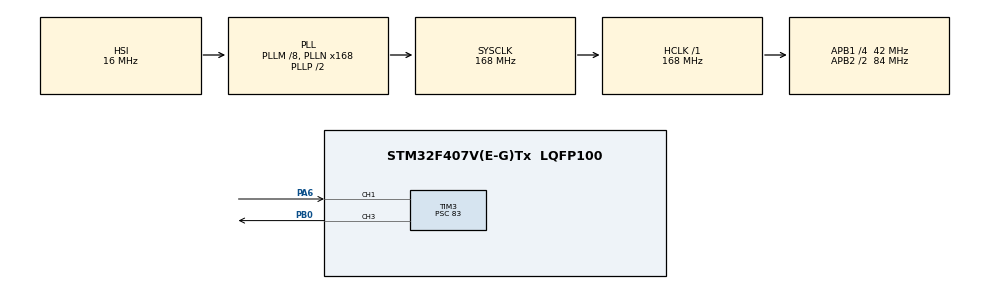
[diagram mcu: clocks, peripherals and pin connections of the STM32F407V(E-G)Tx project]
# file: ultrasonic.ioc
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Mcu.Family=STM32F4
Mcu.Name=STM32F407V(E-G)Tx
Mcu.Package=LQFP100
NVIC.PriorityGroup=NVIC_PRIORITYGROUP_4
NVIC.TIM3_IRQn=true\:1\:0\:true\:false\:true\:true\:true
PA6.Signal=S_TIM3_CH1
PB0.Signal=S_TIM3_CH3
PH0-OSC_IN.Mode=HSE-External-Oscillator
PH0-OSC_IN.Signal=RCC_OSC_IN
PH1-OSC_OUT.Mode=HSE-External-Oscillator
PH1-OSC_OUT.Signal=RCC_OSC_OUT
ProjectManager.HeapSize=0x200
ProjectManager.StackSize=0x400
ProjectManager.TargetToolchain=MDK-ARM V5
RCC.48MHZClocksFreq_Value=84000000
RCC.AHBFreq_Value=168000000
RCC.APB1CLKDivider=RCC_HCLK_DIV4
RCC.APB1Freq_Value=42000000
RCC.APB1TimFreq_Value=84000000
RCC.APB2CLKDivider=RCC_HCLK_DIV2
RCC.APB2Freq_Value=84000000
RCC.APB2TimFreq_Value=168000000
RCC.CortexFreq_Value=168000000
RCC.HCLKFreq_Value=168000000
RCC.HSE_VALUE=25000000
RCC.HSI_VALUE=16000000
RCC.LSE_VALUE=32768
RCC.PLLM=8
RCC.PLLN=168
RCC.SYSCLKFreq_VALUE=168000000
RCC.SYSCLKSource=RCC_SYSCLKSOURCE_PLLCLK
RCC.VCOOutputFreq_Value=336000000
SH.S_TIM3_CH1.0=TIM3_CH1,Input_Capture1_from_TI1
SH.S_TIM3_CH1.1=TIM3_CH1,Input_Capture2_from_TI1
SH.S_TIM3_CH3.0=TIM3_CH3,PWM Generation3 CH3
TIM3.Channel-Input_Capture1_from_TI1=TIM_CHANNEL_1
TIM3.Channel-Input_Capture2_from_TI1=TIM_CHANNEL_2
TIM3.Channel-PWM\ Generation3\ CH3=TIM_CHANNEL_3
TIM3.Period=33332
TIM3.Prescaler=83
TIM3.Pulse-PWM\ Generation3\ CH3=19
VP_TIM3_VS_ClockSourceINT.Mode=Internal
board=custom

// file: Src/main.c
/* USER CODE BEGIN Header */
/**
  ******************************************************************************
  * @file           : main.c
  * @brief          : Main program body
  ******************************************************************************
  * @attention
  *
  * <h2><center>&copy; Copyright (c) 2020 STMicroelectronics.
  * All rights reserved.</center></h2>
  *
  * This software component is licensed by ST under BSD 3-Clause license,
  * the "License"; You may not use this file except in compliance with the
  * License. You may obtain a copy of the License at:
  *                        opensource.org/licenses/BSD-3-Clause
  *
  ******************************************************************************
  */
/* USER CODE END Header */

#include "main.h"
#include "tim.h"
#include "gpio.h"

/* USER CODE BEGIN Includes */
#include "LiquidCrystal.h"

/* USER CODE END Includes */

/* USER CODE BEGIN PV */
uint16_t echo_start = 0;
uint16_t RTT = 0;
char LCDstring[16] = "";
float distance = 0;
/* USER CODE END PV */

void SystemClock_Config(void);

int main(void)
{

  /* MCU Configuration--------------------------------------------------------*/

  /* Reset of all peripherals, Initializes the Flash interface and the Systick. */
  HAL_Init();

  /* Configure the system clock */
  SystemClock_Config();

  /* Initialize all configured peripherals */
  MX_GPIO_Init();
  MX_TIM3_Init();
  /* USER CODE BEGIN 2 */
	HAL_TIM_PWM_Start(&htim3, TIM_CHANNEL_3);
	HAL_TIM_IC_Start_IT(&htim3, TIM_CHANNEL_1);
	HAL_TIM_IC_Start_IT(&htim3, TIM_CHANNEL_2);
	LiquidCrystal(GPIOD, GPIO_PIN_9, GPIO_PIN_10, GPIO_PIN_11,
			     GPIO_PIN_0, GPIO_PIN_1, GPIO_PIN_2, GPIO_PIN_3);
  /* USER CODE END 2 */

  /* Infinite loop */
  while (1)
  {

    /* USER CODE BEGIN 3 */
		clear();

		setCursor(0,0);
		sprintf(LCDstring, "RTT = %d", 342*RTT); // micro-meter
		print(LCDstring);

		setCursor(0,1);
		distance = 0.0348*RTT/2.0 - 0.4472;
		sprintf(LCDstring, "dis: %f", distance);
		print(LCDstring);
		HAL_Delay(200);
  }
  /* USER CODE END 3 */
}

void SystemClock_Config(void)
{
  RCC_OscInitTypeDef RCC_OscInitStruct = {0};
  RCC_ClkInitTypeDef RCC_ClkInitStruct = {0};

  /** Configure the main internal regulator output voltage
  */
  __HAL_RCC_PWR_CLK_ENABLE();
  __HAL_PWR_VOLTAGESCALING_CONFIG(PWR_REGULATOR_VOLTAGE_SCALE1);
  /** Initializes the CPU, AHB and APB busses clocks
  */
  RCC_OscInitStruct.OscillatorType = RCC_OSCILLATORTYPE_HSI;
  RCC_OscInitStruct.HSIState = RCC_HSI_ON;
  RCC_OscInitStruct.HSICalibrationValue = RCC_HSICALIBRATION_DEFAULT;
  RCC_OscInitStruct.PLL.PLLState = RCC_PLL_ON;
  RCC_OscInitStruct.PLL.PLLSource = RCC_PLLSOURCE_HSI;
  RCC_OscInitStruct.PLL.PLLM = 8;
  RCC_OscInitStruct.PLL.PLLN = 168;
  RCC_OscInitStruct.PLL.PLLP = RCC_PLLP_DIV2;
  RCC_OscInitStruct.PLL.PLLQ = 4;
  if (HAL_RCC_OscConfig(&RCC_OscInitStruct) != HAL_OK)
  {
    Error_Handler();
  }
  /** Initializes the CPU, AHB and APB busses clocks
  */
  RCC_ClkInitStruct.ClockType = RCC_CLOCKTYPE_HCLK|RCC_CLOCKTYPE_SYSCLK
                              |RCC_CLOCKTYPE_PCLK1|RCC_CLOCKTYPE_PCLK2;
  RCC_ClkInitStruct.SYSCLKSource = RCC_SYSCLKSOURCE_PLLCLK;
  RCC_ClkInitStruct.AHBCLKDivider = RCC_SYSCLK_DIV1;
  RCC_ClkInitStruct.APB1CLKDivider = RCC_HCLK_DIV4;
  RCC_ClkInitStruct.APB2CLKDivider = RCC_HCLK_DIV2;

  if (HAL_RCC_ClockConfig(&RCC_ClkInitStruct, FLASH_LATENCY_5) != HAL_OK)
  {
    Error_Handler();
  }
}

/* USER CODE BEGIN 4 */

void HAL_TIM_IC_CaptureCallback(TIM_HandleTypeDef *htim)
{
	if (htim->Channel == HAL_TIM_ACTIVE_CHANNEL_1)
	{
		echo_start = HAL_TIM_ReadCapturedValue(&htim3, TIM_CHANNEL_1);
	}
	if (htim->Channel == HAL_TIM_ACTIVE_CHANNEL_2)
	{
		RTT = TIM3->CCR2 - echo_start;
	}
}
/* USER CODE END 4 */

void Error_Handler(void)
{
}

/************************ (C) COPYRIGHT STMicroelectronics *****END OF FILE****/
